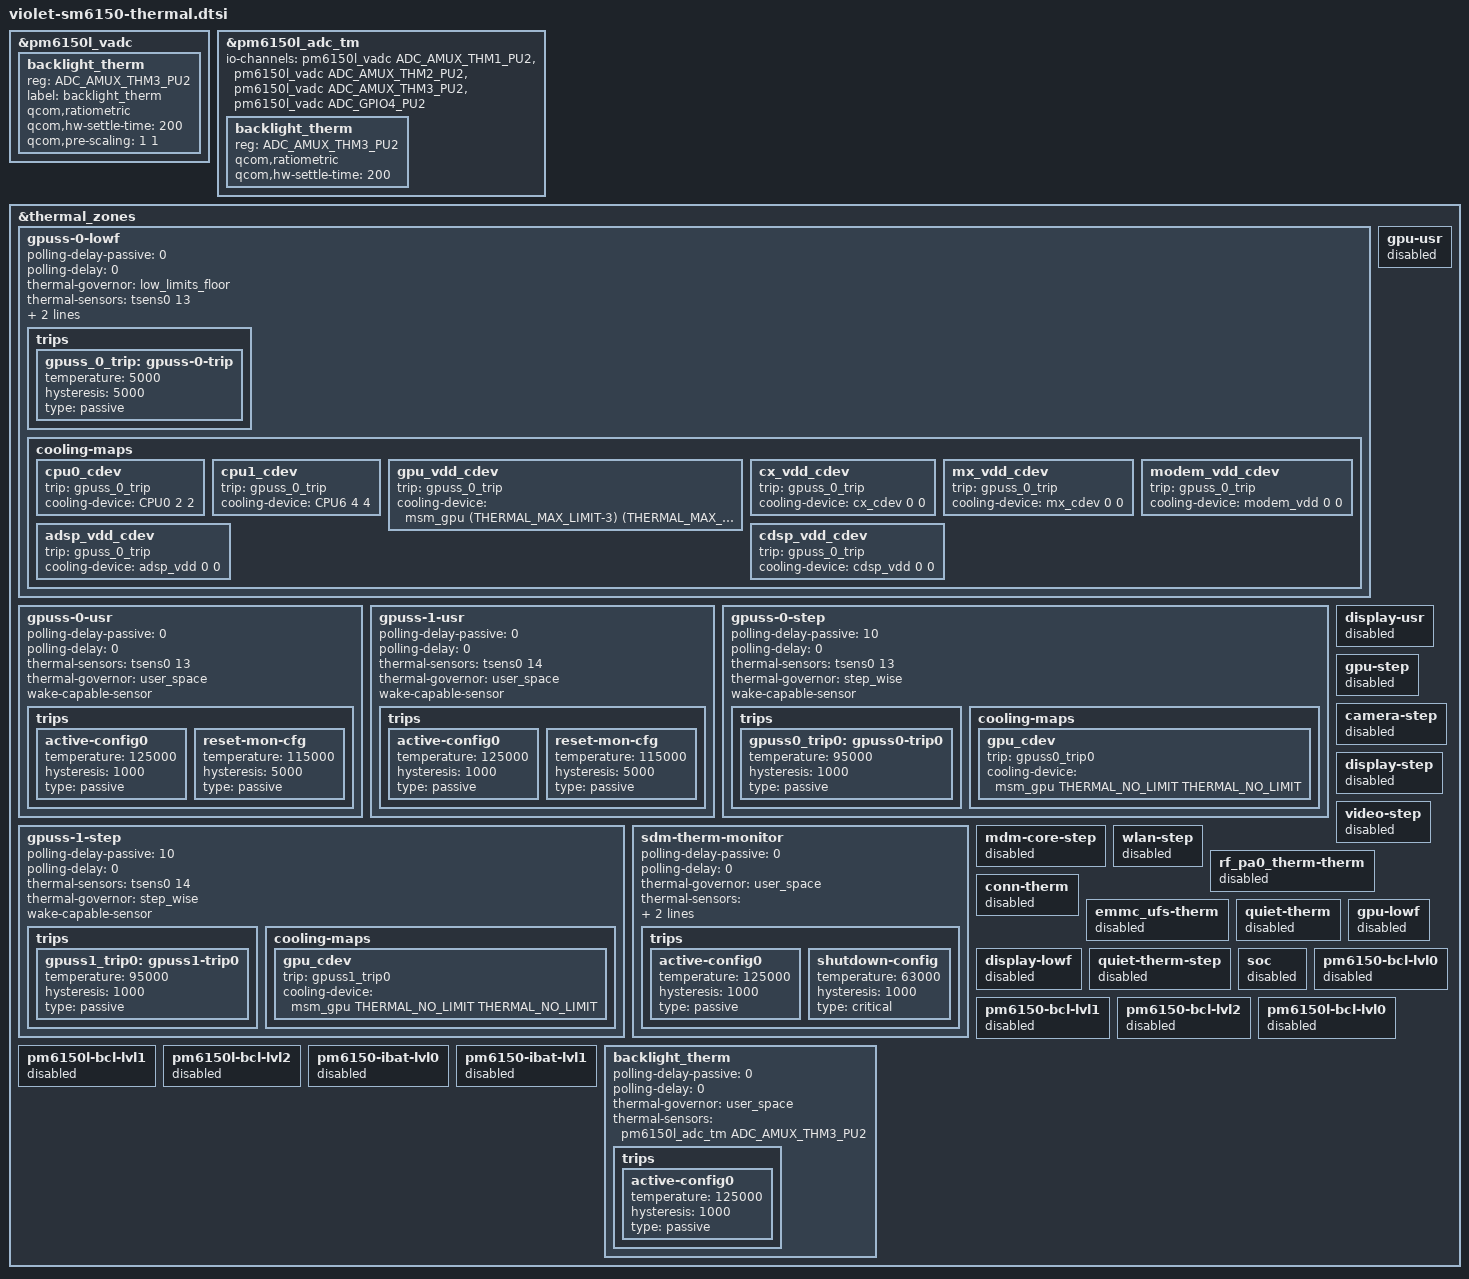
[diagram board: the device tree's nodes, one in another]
/*
 * Copyright (C) 2021 The LineageOS Project
 *
 * this file is for attribution only of violet
 * And public attribution of Xiaomi platforms (like F7B and so)
 */

&pm6150l_vadc {
    /delete-node/ rf_pa1_therm;
    backlight_therm {
        reg = <ADC_AMUX_THM3_PU2>;
        label = "backlight_therm";
        qcom,ratiometric;
        qcom,hw-settle-time = <200>;
        qcom,pre-scaling = <1 1>;
    };
};

&pm6150l_adc_tm {
    io-channels =
        <&pm6150l_vadc ADC_AMUX_THM1_PU2>,
        <&pm6150l_vadc ADC_AMUX_THM2_PU2>,
        <&pm6150l_vadc ADC_AMUX_THM3_PU2>,
        <&pm6150l_vadc ADC_GPIO4_PU2>;

    /delete-node/ camera_flash_therm;
    backlight_therm {
        reg = <ADC_AMUX_THM3_PU2>;
        qcom,ratiometric;
        qcom,hw-settle-time = <200>;
    };
};

&thermal_zones {
	gpuss-0-lowf {
		polling-delay-passive = <0>;
		polling-delay = <0>;
		thermal-governor = "low_limits_floor";
		thermal-sensors = <&tsens0 13>;
		wake-capable-sensor;
		tracks-low;
		trips {
			gpuss_0_trip: gpuss-0-trip {
				temperature = <5000>;
				hysteresis = <5000>;
				type = "passive";
			};
		};

		cooling-maps {
			cpu0_cdev {
				trip = <&gpuss_0_trip>;
				cooling-device = <&CPU0 2 2>;
			};

			cpu1_cdev {
				trip = <&gpuss_0_trip>;
				cooling-device = <&CPU6 4 4>;
			};

			gpu_vdd_cdev {
				trip = <&gpuss_0_trip>;
				cooling-device = <&msm_gpu (THERMAL_MAX_LIMIT-3)
							(THERMAL_MAX_LIMIT-3)>;
			};

			cx_vdd_cdev {
				trip = <&gpuss_0_trip>;
				cooling-device = <&cx_cdev 0 0>;
			};

			mx_vdd_cdev {
				trip = <&gpuss_0_trip>;
				cooling-device = <&mx_cdev 0 0>;
			};

			modem_vdd_cdev {
				trip = <&gpuss_0_trip>;
				cooling-device = <&modem_vdd 0 0>;
			};

			adsp_vdd_cdev {
				trip = <&gpuss_0_trip>;
				cooling-device = <&adsp_vdd 0 0>;
			};

			cdsp_vdd_cdev {
				trip = <&gpuss_0_trip>;
				cooling-device = <&cdsp_vdd 0 0>;
			};
		};
	};	

	gpuss-0-usr {
		polling-delay-passive = <0>;
		polling-delay = <0>;
		thermal-sensors = <&tsens0 13>;
		thermal-governor = "user_space";
		wake-capable-sensor;
		trips {
			active-config0 {
				temperature = <125000>;
				hysteresis = <1000>;
				type = "passive";
			};
			reset-mon-cfg {
				temperature = <115000>;
				hysteresis = <5000>;
				type = "passive";
			};
		};
	};

	gpuss-1-usr {
		polling-delay-passive = <0>;
		polling-delay = <0>;
		thermal-sensors = <&tsens0 14>;
		thermal-governor = "user_space";
		wake-capable-sensor;
		trips {
			active-config0 {
				temperature = <125000>;
				hysteresis = <1000>;
				type = "passive";
			};
			reset-mon-cfg {
				temperature = <115000>;
				hysteresis = <5000>;
				type = "passive";
			};
		};
	};

	gpuss-0-step {
		polling-delay-passive = <10>;
		polling-delay = <0>;
		thermal-sensors = <&tsens0 13>;
		thermal-governor = "step_wise";
		wake-capable-sensor;
		trips {
			gpuss0_trip0: gpuss0-trip0 {
				temperature = <95000>;
				hysteresis = <1000>;
				type = "passive";
			};
		};

		cooling-maps {
			gpu_cdev {
				trip = <&gpuss0_trip0>;
				cooling-device = <&msm_gpu THERMAL_NO_LIMIT
							THERMAL_NO_LIMIT>;
			};
		};
	};

	gpuss-1-step {
		polling-delay-passive = <10>;
		polling-delay = <0>;
		thermal-sensors = <&tsens0 14>;
		thermal-governor = "step_wise";
		wake-capable-sensor;
		trips {
			gpuss1_trip0: gpuss1-trip0 {
				temperature = <95000>;
				hysteresis = <1000>;
				type = "passive";
			};
		};

		cooling-maps {
			gpu_cdev {
				trip = <&gpuss1_trip0>;
				cooling-device = <&msm_gpu THERMAL_NO_LIMIT
							THERMAL_NO_LIMIT>;
			};
		};
	};

	sdm-therm-monitor {
		polling-delay-passive = <0>;
		polling-delay = <0>;
		thermal-governor = "user_space";
		thermal-sensors = <&pm6150l_adc_tm ADC_AMUX_THM2_PU2>;
		wake-capable-sensor;
		trips {
			active-config0 {
				temperature = <125000>;
				hysteresis = <1000>;
				type = "passive";
			};
			shutdown-config {
				temperature = <63000>;
				hysteresis = <1000>;
				type = "critical";
			};
		};
	};

	/* Remove redundant QCT thermal zones */
	gpu-usr {
		status = "disabled";
	};

	display-usr {
		status = "disabled";
	};

	gpu-step {
		status = "disabled";
	};

	camera-step {
		status = "disabled";
	};

	mdm-core-step {
		status = "disabled";
	};

	display-step {
		status = "disabled";
	};

	video-step {
		status = "disabled";
	};

	wlan-step {
		status = "disabled";
	};

	rf_pa0_therm-therm {
		status = "disabled";
	};

	conn-therm {
		status = "disabled";
	};

	emmc_ufs-therm {
		status = "disabled";
	};

	quiet-therm {
		status = "disabled";
	};

	gpu-lowf {
		status = "disabled";
	};

	display-lowf {
		status = "disabled";
	};

	quiet-therm-step {
		status = "disabled";
	};

	/* Disable QCT default BCL throttling */
	soc {
		status = "disabled";
	};

	pm6150-bcl-lvl0 {
		status = "disabled";
	};

	pm6150-bcl-lvl1	{
		status = "disabled";
	};

	pm6150-bcl-lvl2	{
		status = "disabled";
	};

	pm6150l-bcl-lvl0 {
		status = "disabled";
	};

	pm6150l-bcl-lvl1 {
		status = "disabled";
	};

	pm6150l-bcl-lvl2 {
		status = "disabled";
	};

	pm6150-ibat-lvl0 {
		status = "disabled";
	};

	pm6150-ibat-lvl1 {
		status = "disabled";
	};
	
	backlight_therm {
        	polling-delay-passive = <0>;
        	polling-delay = <0>;
        	thermal-governor = "user_space";
        	thermal-sensors = <&pm6150l_adc_tm ADC_AMUX_THM3_PU2>;
        	trips {
            		active-config0 {
                	temperature = <125000>;
                	hysteresis = <1000>;
                	type = "passive";
            		};
        	};
    	};
};
